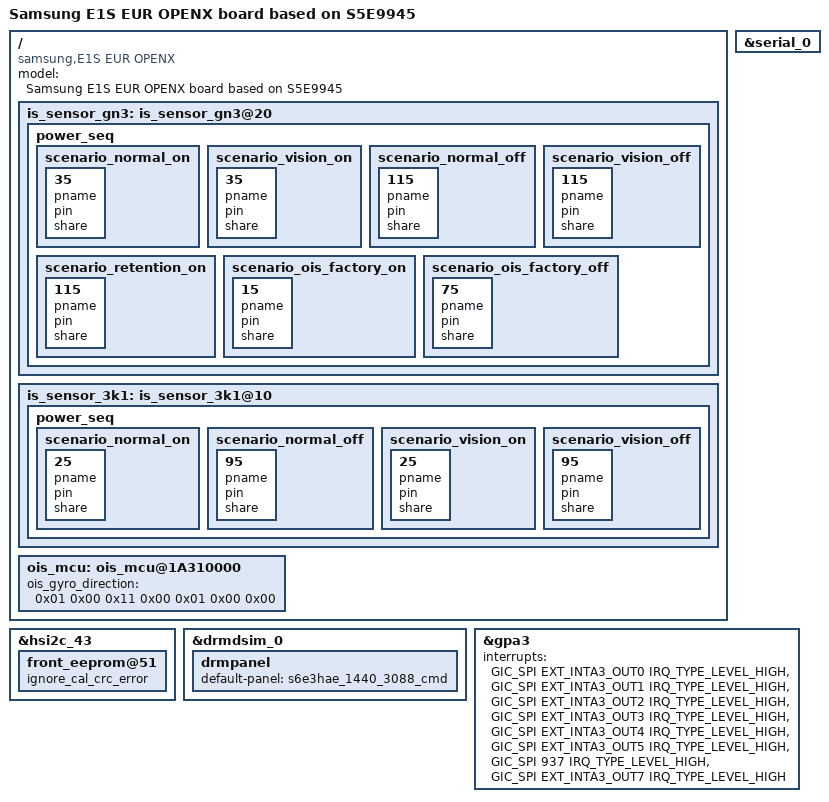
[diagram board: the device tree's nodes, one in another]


/*
 * SAMSUNG S5E9945 board device tree source
 *
 * Copyright (c) 2023 Samsung Electronics Co., Ltd.
 *		http://www.samsung.com
 *
 * This program is free software; you can redistribute it and/or modify
 * it under the terms of the GNU General Public License version 2 as
 * published by the Free Software Foundation.
 */

#include "s5e9945-e1s_pm_00.dtsi"
#include "s5e9945_evt0-e1s_common.dtsi"
#include "s5e9945-e1s_bluetooth_00.dtsi"
#include "../../exynos/board/erd/panel/samsung-emulation-video-panel.dtsi"
#include "../../exynos/board/erd/panel/samsung-s6e3hae-1440-3088-command-panel.dtsi"
#include "s5e9945-e1s_wifi_02.dtsi"

/ {
	compatible = "samsung,E1S EUR OPENX", "samsung,S5E9945";

	fragment@model {
		target-path = "/";
		__overlay__ {
			#address-cells = <2>;
			#size-cells = <1>;

			model = "Samsung E1S EUR OPENX board based on S5E9945";
		}; /* end of __overlay__ */
	}; /* end of fragment */

	fragment@camera {
		target-path = "/";
		__overlay__ {
			is_sensor_gn3: is_sensor_gn3@20 {
				power_seq {
					scenario_normal_on {
						35 { pname; pin; share; };
					};
					scenario_vision_on {
						35 { pname; pin; share; };
					};
					scenario_normal_off {
						115 { pname; pin; share; };
					};
					scenario_vision_off {
						115 { pname; pin; share; };
					};
					scenario_retention_on {
						115 { pname; pin; share; };
					};
					scenario_ois_factory_on {
						15 { pname; pin; share; };
					};
					scenario_ois_factory_off {
						75 { pname; pin; share; };
					};
				};
			};

			is_sensor_3k1: is_sensor_3k1@10 {
				power_seq {
					scenario_normal_on {
						25 { pname; pin; share; };
					};
					scenario_normal_off {
						95 { pname; pin; share; };
					};
					scenario_vision_on {
						25 { pname; pin; share; };
					};
					scenario_vision_off {
						95 { pname; pin; share; };
					};
				};
			};

			ois_mcu: ois_mcu@1A310000 {
				ois_gyro_direction = <0x01 0x00 0x11 0x00 0x01 0x00 0x00>;
			};
		};
	};
}; /* end of root */

&hsi2c_43 {
	front_eeprom@51 {
		ignore_cal_crc_error;
	};
};

&serial_0 {
	status = "okay";
};

&drmdsim_0 {
	drmpanel {
		default-panel = "s6e3hae_1440_3088_cmd";
	};
};

&gpa3 {
	interrupts = <GIC_SPI EXT_INTA3_OUT0 IRQ_TYPE_LEVEL_HIGH>, <GIC_SPI EXT_INTA3_OUT1 IRQ_TYPE_LEVEL_HIGH>,
				 <GIC_SPI EXT_INTA3_OUT2 IRQ_TYPE_LEVEL_HIGH>, <GIC_SPI EXT_INTA3_OUT3 IRQ_TYPE_LEVEL_HIGH>,
				 <GIC_SPI EXT_INTA3_OUT4 IRQ_TYPE_LEVEL_HIGH>, <GIC_SPI EXT_INTA3_OUT5 IRQ_TYPE_LEVEL_HIGH>,
				 <GIC_SPI 937 IRQ_TYPE_LEVEL_HIGH>, <GIC_SPI EXT_INTA3_OUT7 IRQ_TYPE_LEVEL_HIGH>;
};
